# RZT2ME register map
Vendor: Renesas Electronics Corporation; Series: RZT; File version: 1.00.00
CPU: other r0p0, little endian, MPU, no FPU, VTOR, 4 interrupt priority bits, 624 interrupts
Registers are 32-bit, read-write, reset 0x0 unless marked. A register's access mark holds for its fields unless they carry their own. Offsets are from the block's base; [hi:lo] are bit positions; lines under a group give offsets from that group; {n}, {i} and the like mark numbered series.

## ETHSW (part 3 of 3) — Ethernet Switch
Base 0x80120000
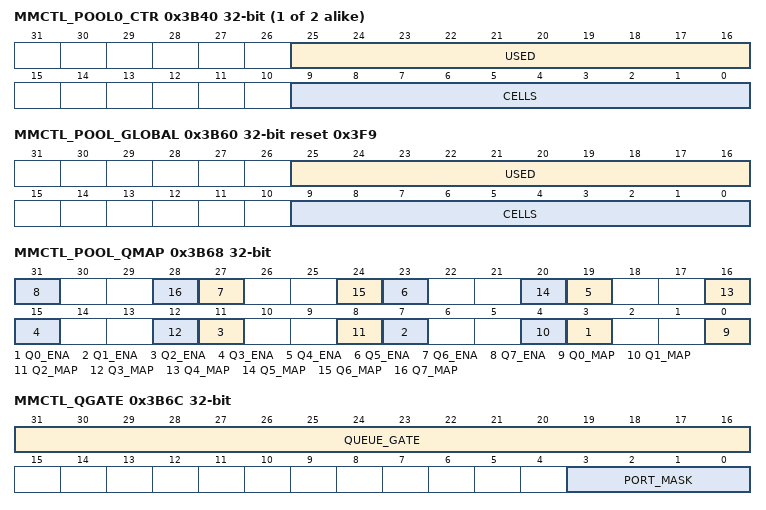
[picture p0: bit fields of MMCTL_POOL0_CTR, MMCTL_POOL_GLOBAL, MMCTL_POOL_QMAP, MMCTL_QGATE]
{0x3B40+4i} MMCTL_POOL{i}_CTR (i=0..1) — Memory Pool Counter (n = 0 to 1)
  [25:16] USED ro — Reports the current available number of used cells for this memory pool. The used number of free cells can be calculated as CELLS - USED.
  [9:0] CELLS — Memory pool configuration for pool n. Configures, in cells, the size of each memory pool.
0x3B60 MMCTL_POOL_GLOBAL reset 0x3F9 — Memory Pool Configuration Register
  [25:16] USED ro — Reports the current number of used cells for the global shared pool. The used number of free cells can be calculated as CELLS - USED.
  [9:0] CELLS — Memory pool configuration for the global pool. Configures, in cells, the size of the global shared pool.
0x3B64 MMCTL_POOL_STATUS ro — Memory Pool Status Register
  [7:0] QUEUE_FULL — Per-queue pool full indication. Indicates for each queue whether all the blocks in the corresponding pool and global pool are allocated.
0x3B68 MMCTL_POOL_QMAP — Queue MAP Register
  [4n+3] Q{n}_ENA (n=0..7) — Queue {n} Memory Pool Enabled
    0=The queue only uses cells from the global pool; 1=The queue uses the pool programmed in Q{n}_MAP
  [4n] Q{n}_MAP (n=0..7) — Queue {n} Memory Pool
0x3B6C MMCTL_QGATE wo — Queue Gate State Register
  [31:16] QUEUE_GATE — 2-bit per queue indicating the action to be performed on each queue of the ports indicated by PORT_MASK.
    0=Hold state, does not change the queue gate state; 1=Toggle state, toggles the gate state; 2=Gate queue, closes the queue; 3=Open queue, enables the queue
  [3:0] PORT_MASK — Per-port bit mask. When set to 1 for a port, the queue gate state is changed for that port as indicated by QUEUE_GATE.
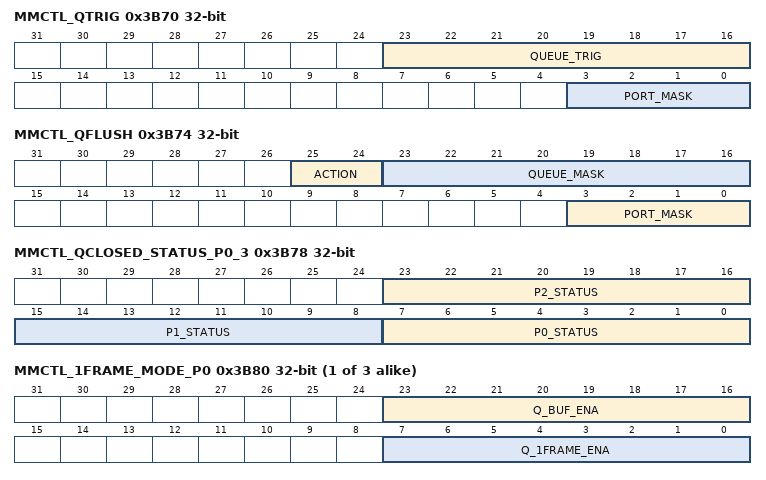
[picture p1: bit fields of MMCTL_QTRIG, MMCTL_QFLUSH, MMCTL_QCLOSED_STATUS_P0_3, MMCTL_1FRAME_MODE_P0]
0x3B70 MMCTL_QTRIG wo — Queue Trigger Register
  [23:16] QUEUE_TRIG — 1-bit per queue indicating from which queues a frame is to be transmitted from the ports indicated by PORT_MASK. When set to 1, a single frame is transmitted per indicated port in PORT_MASK among the queues indicated by QUEUE_TRIG.
  [3:0] PORT_MASK — Per-port bit mask. When set to 1 for a port, a frame is triggered from the closed queues indicated by QUEUE_TRIG.
0x3B74 MMCTL_QFLUSH wo — Flush Event Select Register
  [25:24] ACTION — Selects the flush state for the queues indicated by QUEUE_MASK in the ports indicated by PORT_MASK. Possible actions are:
    0=Disable flush; 1=Flush when queue is closed, discarding any new frames; 2=Flush on queue close until empty, then stops flushing; 3=TRIGGER flush until empty, then return to current flush mode
  [23:16] QUEUE_MASK — 1 bit per queue indicating for which queues of the ports indicated by PORT_MASK the flush state is changed as indicated in ACTION.
  [3:0] PORT_MASK — Per-port bit mask. When set to 1 for a port, the queue flush status is changed for that port for the queues indicated in QUEUE_MASK.
0x3B78 MMCTL_QCLOSED_STATUS_P0_3 ro — Queue Closed Status Register
  [23:16] P2_STATUS — Per-queue closed status of Port 2 (1-bit per queue). A 0 indicates that the queue is open (enabled), and a 1 indicates that the queue is closed (disabled).
  [15:8] P1_STATUS — Per-queue closed status of Port 1 (1-bit per queue). A 0 indicates that the queue is open (enabled), and a 1 indicates that the queue is closed (disabled).
  [7:0] P0_STATUS — Per-queue closed status of Port 0 (1-bit per queue). A 0 indicates that the queue is open (enabled), and a 1 indicates that the queue is closed (disabled).
{0x3B80+4i} MMCTL_1FRAME_MODE_P{i} (i=0..2) — Port {i} 1-Frame Mode Configuration Register
  [23:16] Q_BUF_ENA — 1 bit per queue. Setting a bit to 1 enables the buffer mode behavior for that queue for port n. This mode requires also that Q_1FRAME_ENA is set to 1.
  [7:0] Q_1FRAME_ENA — 1 bit per queue. Setting a bit to 1 enables the 1-frame mode for that queue for port n. In this mode, only one frame is allowed in the queue. If a new frame is received, the old frame is discarded.
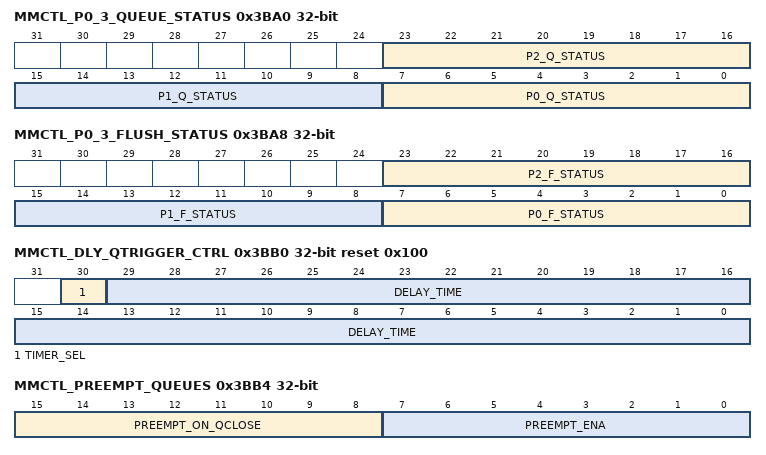
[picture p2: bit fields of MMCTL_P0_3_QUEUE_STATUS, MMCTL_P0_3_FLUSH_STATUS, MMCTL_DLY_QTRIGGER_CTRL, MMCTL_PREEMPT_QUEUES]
0x3BA0 MMCTL_P0_3_QUEUE_STATUS ro — Queue Status Indicator
  [all] fields
    0=Queue is empty; 1=Queued frames
  [23:16] P2_Q_STATUS — Port 2 Per-Queue Bit Indication
  [15:8] P1_Q_STATUS — Port 1 Per-Queue Bit Indication
  [7:0] P0_Q_STATUS — Port 0 Per-Queue Bit Indication
0x3BA8 MMCTL_P0_3_FLUSH_STATUS ro — Queue Flush Status Indicator
  [23:16] P2_F_STATUS — Port 2 per-Queue Bit Indication on whether the queue is flushing frames (read 1) or not (read 0).
  [15:8] P1_F_STATUS — Port 1 per-Queue Bit Indication on whether the queue is flushing frames (read 1) or not (read 0).
  [7:0] P0_F_STATUS — Port 0 per-Queue Bit Indication on whether the queue is flushing frames (read 1) or not (read 0).
0x3BB0 MMCTL_DLY_QTRIGGER_CTRL reset 0x100 — Delayed Queue Trigger Control Register
  [30] TIMER_SEL — Select the source timer to use for calculating the time.
    0=Timer 0; 1=Timer 1
  [29:0] DELAY_TIME — 30-bit time in nanoseconds indicates the time after the trigger request from the pattern matchers to generate the event.
0x3BB4 MMCTL_PREEMPT_QUEUES — Preemptable Queues Configures Register
  [15:8] PREEMPT_ON_QCLOSE — Per-queue configuration bit to enable preempting a frame when the queue goes from OPEN to CLOSED. When the corresponding bit is set to 1 and the queue is configured as preemptable in PREEMPT_ENA, a queue close event causes the current frame to be preempted, if preemption is operational.
  [7:0] PREEMPT_ENA — Per-queue enable bit to configure which queues are used for preemptable traffic. Set to 1 the corresponding bit to configure a queue to be preemptable.
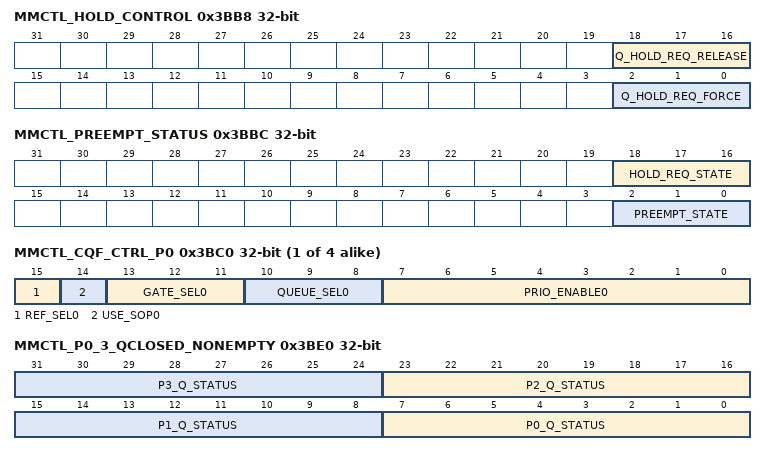
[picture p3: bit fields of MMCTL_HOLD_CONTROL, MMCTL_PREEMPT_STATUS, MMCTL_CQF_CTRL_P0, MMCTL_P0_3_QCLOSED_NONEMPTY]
0x3BB8 MMCTL_HOLD_CONTROL — Request Preemption Register
  [18:16] Q_HOLD_REQ_RELEASE — A per-port bit that forces a release of preemption request using MM_CTL.request (hold_req). When this bit is set to 1, it overrides other sources of hold request, including the TDMA controller and Q_HOLD_REQ_FORCE[2:0].
  [2:0] Q_HOLD_REQ_FORCE — A per-port bit that forces a preempt request using MM_CTL.request (hold_req). When this bit is set to 1, it overrides other sources of hold request, including the TDMA controller.
0x3BBC MMCTL_PREEMPT_STATUS ro — Preemption State Register
  [18:16] HOLD_REQ_STATE — A per-port bit that indicates if a port is preempted using MM_CTL.request (hold_req). This is a real-time indication meant for debugging.
  [2:0] PREEMPT_STATE — A per-port bit that indicates if a port is in a preempted state. This is a real-time indication meant for debugging.
{0x3BC0+4i} MMCTL_CQF_CTRL_P{i} (i=0..3) — Port {i} Cyclic Queuing and Forwarding Control Register (n = 0 to 3)
  [15] REF_SEL0 — Select whether the gate control signal used for the CQF group is based on the egress port when set to 0, or the ingress port when set to 1.
  [14] USE_SOP0 — When set to 1, the CFQ queue is determined when the SOP is received at the frame writer in the memory controller. When set to 0, the queue is determined when the EOP is received at the frame writer.
  [13:11] GATE_SEL0 — Select which gate control signal is used for selecting the output queue (these signals are the same as the ETHSW_TDMAOUT pins).
  [10:8] QUEUE_SEL0 — Select which two physical queues are used for CQF. The queues used are QUEUE_SEL0 and QUEUE_SEL0 + 1. Frames are written into QUEUE_SEL0 when the gate control selected with GATE_SEL0 is 0, and into QUEUE_SEL0 + 1 when the gate control is 1.
  [7:0] PRIO_ENABLE0 — A per-queue enable to select which ingress priorities are queued in the two CQF queues.
0x3BE0 MMCTL_P0_3_QCLOSED_NONEMPTY ro — Port Queue Status Register
  [8n+7:8n] P{n}_Q_STATUS (n=0..3) — Port {n} per-queue bit indication on whether the queue transitioned from open to closed state while frames were still queued.
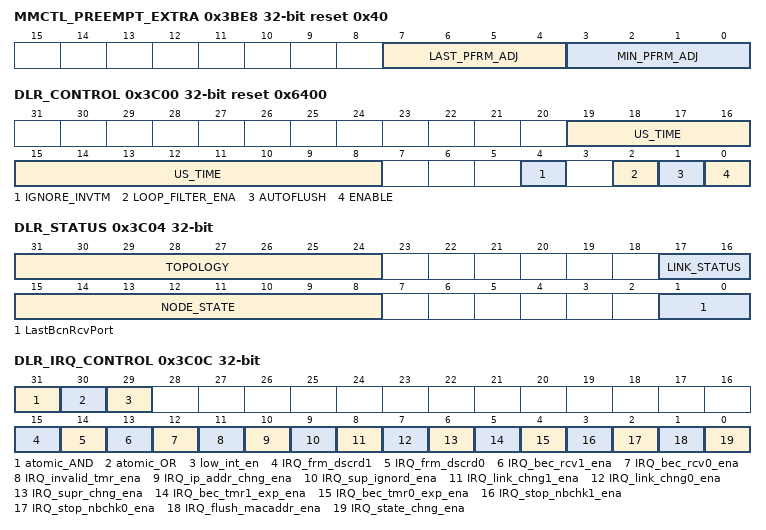
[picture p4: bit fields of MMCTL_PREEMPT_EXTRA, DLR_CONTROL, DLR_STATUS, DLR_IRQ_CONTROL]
0x3BE8 MMCTL_PREEMPT_EXTRA reset 0x40 — Frame Preemption Extra Configuration Register
  [7:4] LAST_PFRM_ADJ — Adjust the preemptable threshold when reaching the end of the frame, in increments of 4 bytes. Incrementing this value increments the length of the last mPacket.
  [3:0] MIN_PFRM_ADJ — Adjust the minimum mPacket length, in increments of 4 bytes.
0x3C00 DLR_CONTROL reset 0x6400
  [19:8] US_TIME — Number of clock cycles required for 1 microsecond for the switch operating clock. This LSI operates at 200 MHz, therefore this register must be set to 0xC8. The value after reset must be changed.
  [4] IGNORE_INVTM — Enable ignore beacon frames with invalid timeout timer. When enabled (set to 1) frames with timeout timer value not within a range of 200 microseconds to 500 milliseconds are ignored and parameters are not locally stored or considered for state transitions. The invalid timeout timer value is always stored within the DLR_INV_TMOUT register irrespective of the value of this bit. Ignored frames are forwarded normally.
  [2] LOOP_FILTER_ENA — Enable the loop filter function. When set to 1, the ingress loop filter is enabled. This can be enabled regardless of the DLR ENABLE state, allowing the loop filter function to operate when DLR is not used.
  [1] AUTOFLUSH — Enable automatic flushing of unicast entries in address table if ring reconfiguration occurs (see also DLR interrupt IRQ_flush_macaddr_ena in DLR_IRQ_CONTROL).
  [0] ENABLE — Enable DLR extension module. When set, the DLR module becomes active. When DLR is enabled, the LOOP_FILTER_ENA must also be enabled for proper DLR operation.
0x3C04 DLR_STATUS ro
  [31:24] TOPOLOGY — Current Network Topology
    0=Linear topology when local node is in IDLE state; 1=Ring topology when local node is not in IDLE state; other=Others (Reserved)
  [17:16] LINK_STATUS
  [15:8] NODE_STATE — Local Node Current State
    0=IDLE_STATE; 1=NORMAL_STATE; 2=FAULT_STATE; other=Others (Reserved)
  [1:0] LastBcnRcvPort — Last Beacon Receive Port
0x3C08 DLR_ETH_TYP reset 0x80E1 — DLR Ethernet Type Register
  [15:0] DLR_ETH_TYP — Ethernet type to compare for DLR frame detection (initial value is 0x80E1)
0x3C0C DLR_IRQ_CONTROL — DLR Interrupt Control Register
  [31] atomic_AND wo — When set during a register-write, the enable bits are ANDed with the current setting of the register. By writing this bit at the same time, only the target bit can be set to 0.
  [30] atomic_OR wo — When set during a register-write, the enable bits are ORed into the current setting of the register. By writing this bit at the same time, only the target bit can be set to 1.
  [29] low_int_en — Enable active-low interrupt. Asserted to use active-low interrupt signal instead of active-high interrupt signal.
  [15] IRQ_frm_dscrd1 — Enable Interrupt on Frame discard due to source address match with the local address on port 1.
  [14] IRQ_frm_dscrd0 — Enable interrupt on frame discard due to source address match with the local address on port 0.
  [13] IRQ_bec_rcv1_ena — Enable interrupt on beacon frame detection on port 1.
  [12] IRQ_bec_rcv0_ena — Enable interrupt on beacon frame detection on port 0.
  [11] IRQ_invalid_tmr_ena — Enable interrupt on invalid range for beacon timeout timer value detection.
  [10] IRQ_ip_addr_chng_ena — Enable interrupt on IP address change detection within beacon frame from ring supervisor.
  [9] IRQ_sup_ignord_ena — Enable interrupt on beacon frame detection from a supervisor with lower precedence than the current ring supervisor or lower numeric value for MAC address when precedence is same.
  [8] IRQ_link_chng1_ena — Enable Link Status Change Interrupt Event for Port 1.
  [7] IRQ_link_chng0_ena — Enable Link Status Change Interrupt Event for Port 0.
  [6] IRQ_supr_chng_ena — Enable Interrupt on Ring Supervisor Change.
  [5] IRQ_bec_tmr1_exp_ena — Enable Interrupt on Beacon Timeout Timer Expire for Port 1.
  [4] IRQ_bec_tmr0_exp_ena
  [3] IRQ_stop_nbchk1_ena — Enable Stop Request Neighbor Check Timeout Timer Interrupt for Port 1.
  [2] IRQ_stop_nbchk0_ena — Enable Stop Request Neighbor Check Timeout Timer Interrupt for Port 0.
  [1] IRQ_flush_macaddr_ena — Enable Flush Local MAC Address Table Interrupt.
  [0] IRQ_state_chng_ena — Enable Interrupt for State Change
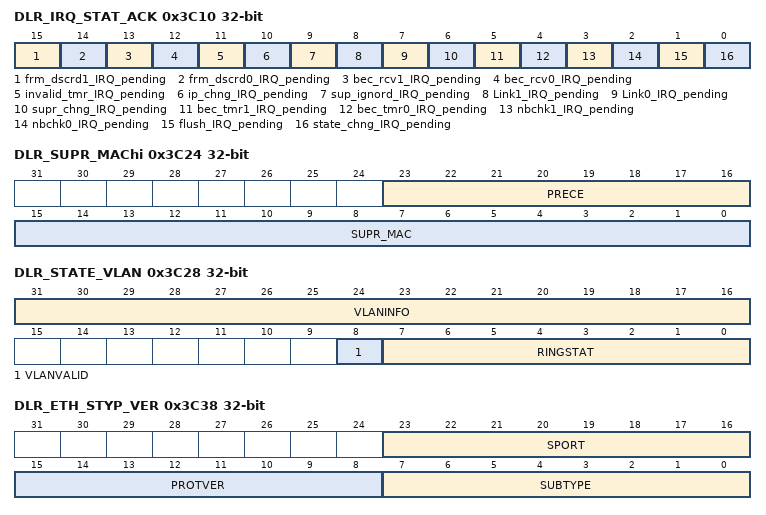
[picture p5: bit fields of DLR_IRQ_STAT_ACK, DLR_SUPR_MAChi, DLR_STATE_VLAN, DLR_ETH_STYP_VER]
0x3C10 DLR_IRQ_STAT_ACK — DLR Interrupt Status/ACK Register
  [15] frm_dscrd1_IRQ_pending — Latched Event on Frame Discard Due to Source Address Match with the Local Address on Port 1 (Loop Filter)
  [14] frm_dscrd0_IRQ_pending — Latched Event on Frame Discard Due to Source Address Match with the Local Address on Port 0 (Loop Filter)
  [13] bec_rcv1_IRQ_pending — Latched Event on Beacon Frame Detection on Port 1
  [12] bec_rcv0_IRQ_pending — Latched Event on Beacon Frame Detection on Port 0
  [11] invalid_tmr_IRQ_pending — Latched Event on Invalid Beacon Timeout Timer Value Detection Within Beacon Frame on Port 0 or Port 1
  [10] ip_chng_IRQ_pending — Latched IP Address Change Event
  [9] sup_ignord_IRQ_pending — Latched Event for Beacon Frame Detection from Ignored Supervisor
  [8] Link1_IRQ_pending — Latched Link Status Change Event for Port 1
  [7] Link0_IRQ_pending — Latched Link Status Change Event for Port 0
  [6] supr_chng_IRQ_pending — Latched Supervisor Change Event
  [5] bec_tmr1_IRQ_pending — Beacon Timeout Timer Expire Event for Port 1
  [4] bec_tmr0_IRQ_pending — Beacon Timeout Timer Expire Event for Port 0
  [3] nbchk1_IRQ_pending — Stop Request Event for Neighbor Check Timeout Timer for Port 1
  [2] nbchk0_IRQ_pending — Stop Request Event for Neighbor Check Timeout Timer for Port 0
  [1] flush_IRQ_pending — Latched Flush Event for MAC Address Learning Table
  [0] state_chng_IRQ_pending — Latched State Change Event
0x3C14 DLR_LOC_MAClo — DLR Local MAC Address Low Register
  [31:0] LOC_MAC — First 4 octets of the Local MAC address for loop filter
0x3C18 DLR_LOC_MAChi — DLR Local MAC Address High Register
  [15:0] LOC_MAC — Last 2 octets of local MAC address for loop filter
0x3C20 DLR_SUPR_MAClo ro — DLR Supervisor MAC Address Low Register
  [31:0] SUPR_MAC — First 4 octets of the active ring supervisor of the MAC address extracted from the Source Address field of the beacon frame.
0x3C24 DLR_SUPR_MAChi ro — DLR Supervisor MAC Address High Register
  [23:16] PRECE — Precedence value of the ring supervisor extracted from the Supervisor precedence field of the beacon frame.
  [15:0] SUPR_MAC — Last 2 octets of the active ring supervisor of the MAC address extracted from the Source Address field of the beacon frame.
0x3C28 DLR_STATE_VLAN ro — DLR Ring Status/VLAN Register
  [31:16] VLANINFO — IEEE 802.1Q VLAN Tag control field extracted from the VLAN info field of the beacon frame.
  [8] VLANVALID
  [7:0] RINGSTAT — DLR ring state extracted from the Ring State field of the beacon frame.
    1=RING_NORMAL_STATE; 2=RING_FAULT_STATE; other=Others (Unused)
0x3C2C DLR_BEC_TMOUT ro — DLR Beacon Timeout Register
  [31:0] BEC_TMOUT — Beacon timeout timer value extracted from the Beacon Timeout in microseconds field of the beacon frame.
0x3C30 DLR_BEC_INTRVL ro — DLR Beacon Interval Register
  [31:0] BEC_INTRVL — Beacon interval extracted from the Beacon Interval field of the beacon frame
0x3C34 DLR_SUPR_IPADR ro — DLR Supervisor IP Address Register
  [31:0] SUPR_IPADR — IP address of the ring supervisor extracted from the Source IP address field of the beacon frame. A value of 0x0 can be received when supervisor has no IP address.
0x3C38 DLR_ETH_STYP_VER ro — DLR Sub Type/Protocol Version Register
  [23:16] SPORT — Source port extracted from the Source Port field of the beacon frame.
  [15:8] PROTVER — DLR Ring Protocol Version extracted from the Ring Protocol Version field of the beacon frame.
  [7:0] SUBTYPE — DLR Ring Ether Sub Type extracted from the Ring Sub Type field of the beacon frame.
0x3C3C DLR_INV_TMOUT ro — DLR Beacon Timeout Timer Register
  [31:0] INV_TMOUT — Last out of range Beacon timeout timer value extracted from beacon frame on any of the port.
0x3C40 DLR_SEQ_ID ro — DLR Sequence ID Register
  [31:0] SEQ_ID — Sequence ID of the last beacon frame extracted from the Sequence ID field of the beacon frame on port 0 or port 1. Sequence ID of the ignored frames is not stored.
0x3C58 DLR_DSTlo reset 0x6C2101 — DLR Beacon Destination Address Low Register
  [31:0] DLR_DST — First 4 octets of the beacon frame destination multicast address (01-21-6C-00-00-01).
0x3C5C DLR_DSThi reset 0x100 — DLR Beacon Destination Address High Register
  [15:0] DLR_DST — Last 2 octets of the beacon frame destination multicast address (01-21-6C-00-00-01).
0x3C60 DLR_RX_STAT0 ro — DLR Received Frame Statistic Register 0
  [31:0] RX_STAT0 — Number of Beacon Frames Received on Port 0
0x3C64 DLR_RX_ERR_STAT0 ro — DLR Received Frame Error Statistic Register 0
  [31:0] RX_ERR_STAT0 — Number of Beacon Frames Received with CRC Error on Port 0
0x3C6C DLR_RX_LF_STAT0 — DLR Received Frame Loop Filter Statistic Register 0
  [7:0] RX_LF_STAT0 — Number of discarded frames in port 0 due to loop filtering when LOOP_FILTER_ENA is set to 1. Saturates at 255.
0x3C70 DLR_RX_STAT1 ro — DLR Received Frame Statistic Register 1
  [31:0] RX_STAT1 — Number of Beacon Frames Received on Port 1
0x3C74 DLR_RX_ERR_STAT1 ro — DLR Received Frame Error Statistic Register 1
  [31:0] RX_ERR_STAT1 — Number of Beacon Frames Received with CRC Error on Port 1
0x3C7C DLR_RX_LF_STAT1 — DLR Received Frame Loop Filter Statistic Register 1
  [7:0] RX_LF_STAT1 — Number of discarded frames in port 1 due to loop filtering when LOOP_FILTER_ENA is set to 1. Saturates at 255.
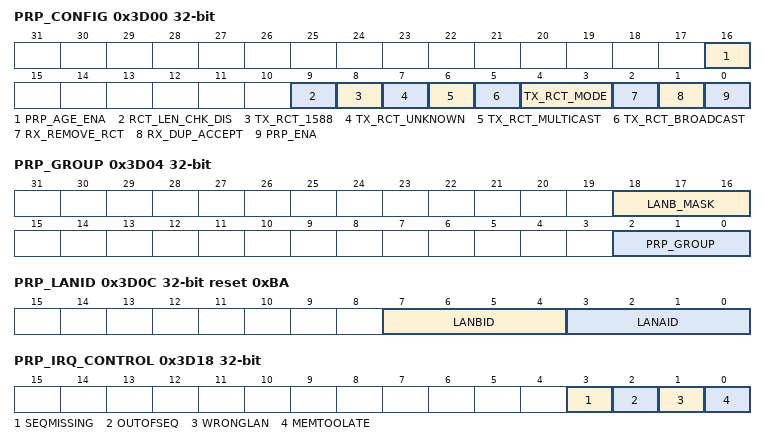
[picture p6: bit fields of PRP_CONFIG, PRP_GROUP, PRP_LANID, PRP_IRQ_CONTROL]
0x3D00 PRP_CONFIG — PRP Configuration Register
  [16] PRP_AGE_ENA — Enable History Memory Aging Timer
  [9] RCT_LEN_CHK_DIS — When set to 1, disables the RCT length field checking against the actual frame length.
  [8] TX_RCT_1588 — Setting this bit affects IEEE 1588 frames that are forwarded through the switch (for example, when used as RedBox) to both PRP_GROUP ports. Locally generated IEEE 1588 frames (peer-delay request/response) are not affected by this setting.
    0=Do not append RCT to IEEE 1588 frames (frame type 0x88F7) frames even if they are duplicated; 1=Allow appending RCT to IEEE 1588 frames. Defines to treat those frames as any other frame according to the configured TX_RCT_xxx settings above.
  [7] TX_RCT_UNKNOWN — Should be 1 normally.
    0=Do not append RCT to frames flooded because the destination is unknown. This further restricts modes 00b, 01b, 11b.; 1=Allow appending RCT to frames that have unknown destination and are hence flooded
  [6] TX_RCT_MULTICAST — Should be 1 normally.
    0=Do not append RCT to multicast frames. This further restricts modes 00b, 01b, 11b.; 1=Allow appending RCT to multicast frames
  [5] TX_RCT_BROADCAST — Should be 1 normally.
    0=Do not append RCT to broadcast frames. This further restricts modes 00b, 01b, 11b.; 1=Allow appending RCT to broadcast frames
  [4:3] TX_RCT_MODE — Control Appending the RCT to Transmitted Frames on the Redundant Ports
    0=Append RCT if group only: Append RCT, if frame is duplicated to exactly the ports listed in the PRP_GROUP register. If the frame is sent to only one of the ports or is for example, flooded also to other ports, no RCT is appended.; 1=Append RCT to group always: Append the RCT always if the frame is duplicated to at least the two ports listed in the PRP_GROUP. This includes flooded frames even if they are additionally sent on other ports outside the PRP_GROUP. If the frame is sent to only one of the PRP_GROUP ports, no RCT is appended.; 2=Disable RCT append: The transmitters do not append the RCT even if frames are duplicated to the PRP_GROUP ports. This represents the IEC: 4.2.6 duplicate accept mode of operation.; 3=Append RCT always forced: The transmitters append the RCT to all frames transmitted on any of the PRP_GROUP ports, no matter if they are duplicated or not or if they are flooded
  [2] RX_REMOVE_RCT — Allow PRP Port RX to Remove the RCT
  [1] RX_DUP_ACCEPT — Enable Duplicate Accept Mode of Operation at Receive
  [0] PRP_ENA — Enable PRP Operation
0x3D04 PRP_GROUP — PRP Port Group Register
  [18:16] LANB_MASK — Defines which of the ports is considered the LAN B port.
  [2:0] PRP_GROUP — Defines which two ports should be treated as redundant ports for PRP.
0x3D08 PRP_SUFFIX reset 0x88FB — PRP RCT Suffix
  [15:0] PRP_SUFFIX — The Redundancy Control Trailer (RCT) suffix (initial value is 0x88FB)
0x3D0C PRP_LANID reset 0xBA — PRP LAN Identifier
  [7:4] LANBID — LAN B Identifier
  [3:0] LANAID — LAN A Identifier
0x3D10 DUP_W — PRP Max Duplicate Detection Window Size
  [7:0] DUP_W — Maximum Duplicate Detect Window Size
0x3D14 PRP_AGETIME — PRP Aging Time Define Register
  [23:0] PRP_AGETIME — Timeout in steps of 32 switch operating clock cycles to control aging of duplicate history data.
0x3D18 PRP_IRQ_CONTROL — PRP Interrupt Control Register
  [3] SEQMISSING — Enable interrupt for frames received and accepted that caused the history to skip a sequence number that was never received (for example, a missing sequence number is being ignored and is now treated as a candidate for dropping).
  [2] OUTOFSEQ — Enable interrupt for frames received and accepted but have an unexpected sequence number.
  [1] WRONGLAN — Enable interrupt for frames received at a redundant port with an invalid LAN identifier in its redundancy trailer.
  [0] MEMTOOLATE — Enable Interrupt for Memory Error Indications.
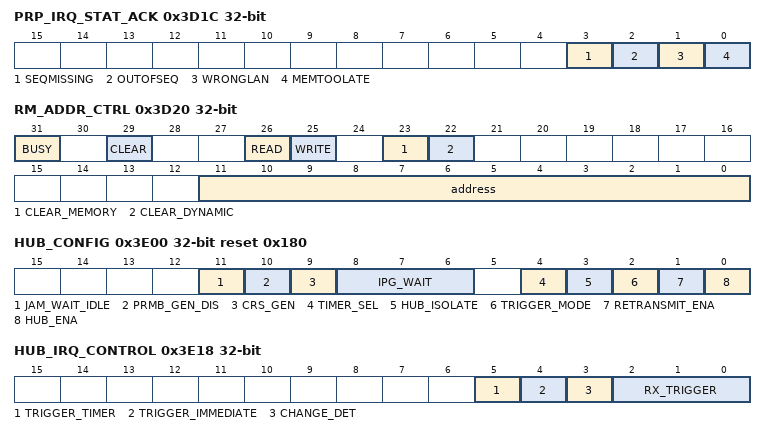
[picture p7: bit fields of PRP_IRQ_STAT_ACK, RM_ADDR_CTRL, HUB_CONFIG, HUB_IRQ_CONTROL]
0x3D1C PRP_IRQ_STAT_ACK — PRP Interrupt Status/ACK Register
  [3] SEQMISSING — This bit functions the same as MEMTOOLATE bit.
  [2] OUTOFSEQ — This bit functions the same as MEMTOOLATE bit.
  [1] WRONGLAN — This bit functions the same as MEMTOOLATE bit.
  [0] MEMTOOLATE — Interrupt Pending Indication
0x3D20 RM_ADDR_CTRL — PRP History Memory Transactions Control Register
  [31] BUSY ro — Transaction Busy Indication
  [29] CLEAR — When set to 1, write all 0s to the entry selected by the given address.
  [26] READ — When set to 1, perform Single Read Transaction.
  [25] WRITE — When set to 1, perform a Single Write Transaction.
  [23] CLEAR_MEMORY — When set to 1, write all memory locations with 0.
  [22] CLEAR_DYNAMIC — When set to 1, scan the complete table for valid dynamic history entries and deletes them (writes entry with all 0s).
  [11:0] address — Memory Address for Read and Write Transactions
0x3D24 RM_DATA — PRP Memory Data Register
  [31:0] RM_DATA — Memory data register for read/write transactions controlled by RM_ADDR_CTRL.
0x3D28 RM_DATA_HI — PRP Memory Data Higher Register
  [31:0] RM_DATA_HI — A Second Data Register
0x3D2C RM_STATUS ro — PRP Memory Controller Status Indication
  [11:0] ageaddress — Address of an entry which the aging process inspects when the aging timer expires next time.
0x3D30 TxSeqTooLate — PRP Frame Transmission Retrieval of Failed Sequence
  [3:0] TxSeqTooLate — Retrieval of a Sequence Number Failed
0x3D34 CntErrWrongLanA ro — PRP Wrong ID LAN-A Count Register
  [31:0] CntErrWrongLanA — Valid frames received on LAN A which have an RCT (valid length + suffix) but LAN ID is not matching LAN A.
0x3D38 CntErrWrongLanB ro — PRP Wrong ID LAN-B Count Register
  [31:0] CntErrWrongLanB — Valid frames received on LAN B which have an RCT (valid length + suffix) but LAN ID is not matching LAN B.
0x3D3C CntDupLanA ro — PRP Duplicate LAN-A Count Register
  [31:0] CntDupLanA — Valid frames received on LAN A that were dropped by duplicate detection.
0x3D40 CntDupLanB ro — PRP Duplicate LAN-B Count Register
  [31:0] CntDupLanB — Valid frames received on LAN B that were dropped by duplicate detection.
0x3D44 CntOutOfSeqLowA ro — PRP Sequence Error Low LAN-A Count Register
  [31:0] CntOutOfSeqLowA — Valid and accepted frames received on LAN A with a sequence number less than last window (DUP_W).
0x3D48 CntOutOfSeqLowB ro — PRP Sequence Error Low LAN-B Count Register
  [31:0] CntOutOfSeqLowB — Valid and accepted frames received on LAN B with a sequence number less than last window (DUP_W).
0x3D4C CntOutOfSeqA ro — PRP Sequence Error LAN-A Count Register
  [31:0] CntOutOfSeqA — Valid and accepted frames received on LAN A with an unexpected sequence number.
0x3D50 CntOutOfSeqB ro — PRP Sequence Error LAN-B Count Register
  [31:0] CntOutOfSeqB — Valid and accepted frames received on LAN B with an unexpected sequence number.
0x3D54 CntAcceptA ro — PRP Valid Frame LAN-A Count Register
  [31:0] CntAcceptA — Valid frames received on LAN A which had a valid sequence number in the expected range.
0x3D58 CntAcceptB ro — PRP Valid Frame LAN-B Count Register
  [31:0] CntAcceptB — Valid frames received on LAN B which had a valid sequence number in the expected range.
0x3D5C CntMissing ro — PRP Drop History Adjustment Count
  [31:0] CntMissing — Indicates adjustment of the drop history as a frame was received with a sequence number of expected + history + 1. This occurs if the same frame was dropped in both LAN segments (one sequence number is missing) and the history is now extended beyond that sequence number (causing it to be treated as drop allowed).
0x3E00 HUB_CONFIG reset 0x180 — HUB Configuration Register
  [11] JAM_WAIT_IDLE
  [10] PRMB_GEN_DIS
  [9] CRS_GEN
  [8:6] IPG_WAIT
  [4] TIMER_SEL — Select the timer to use for timed triggers
    0=Timer 0; 1=Timer 1
  [3] HUB_ISOLATE — Isolate all hub ports from the other ports of the switch and allow communication with management port only. It is then up to the application of the management port to implement some bridging functionality to other ports as required.
  [2] TRIGGER_MODE — Enable Single Frame Trigger Mode
  [1] RETRANSMIT_ENA — Enable Hub Retransmit Capability
  [0] HUB_ENA — Enable Integrated HUB Operation
0x3E04 HUB_GROUP — HUB Port Group Register
  [2:0] HUB_GROUP — Define all ports that should be combined to a Hub Group.
0x3E08 HUB_DEFPORT — HUB Default Port Selection Register
  [2:0] HUB_DEFPORT — The default port within the Hub Group where all traffic from a port outside the group is forwarded to port (bit 0 = port 0, bit 1 = port 1, and bit 2 = port 2). If a frame should be forwarded to any of the hub ports, the frame is sent to this port only. The copy function of the hub copies it to all PHY interfaces of the group eventually.
0x3E0C HUB_TRIGGER_IMMEDIATE — HUB Transmission Trigger Immediate Register
  [2:0] HUB_TRIGGER_IMMEDIATE — Trigger immediate transmission of a single frame from given port within the hub group (bit 0 = port 0, bit 1 = port 1, and bit 2 = port 2).
0x3E10 HUB_TRIGGER_AT — HUB Transmission Trigger At Register
  [2:0] HUB_TRIGGER_AT — Trigger Transmission of a Single Frame at a Specific Time (bit 0 = port 0, bit 1 = port 1, and bit 2 = port 2).
0x3E14 HUB_TTIME — HUB Transmission Time Define Register
  [31:0] HUB_TTIME — Define the Time Value when a Trigger Should Occur
0x3E18 HUB_IRQ_CONTROL — HUB Interrupt Control Register
  [5] TRIGGER_TIMER — Enable interrupt when hub transmit started after writing the HUB_TRIGGER_TIME register and the timeout value is reached (register HUB_TTIME).
  [4] TRIGGER_IMMEDIATE — Enable interrupt when hub transmit started after writing the HUB_TRIGGER_IMMEDIATE register
  [3] CHANGE_DET — Enable interrupt for hub TX state machine port state change request detection
  [2:0] RX_TRIGGER — Enable Interrupt on Receive Pattern Match Trigger Function
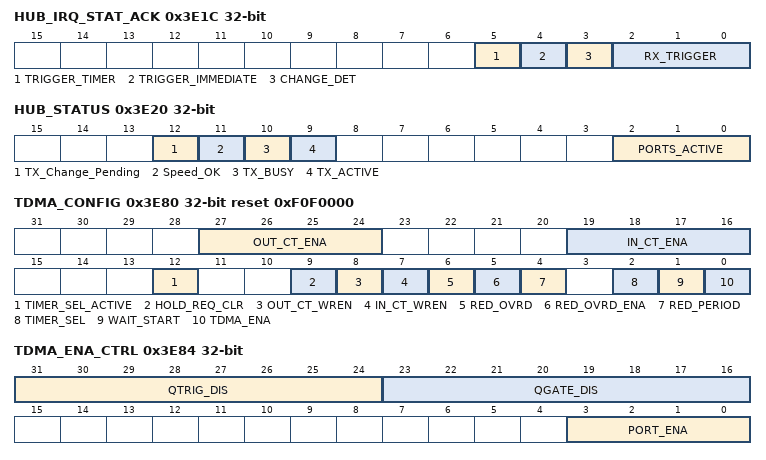
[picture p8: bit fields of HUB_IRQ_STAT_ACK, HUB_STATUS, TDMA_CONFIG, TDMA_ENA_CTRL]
0x3E1C HUB_IRQ_STAT_ACK — HUB Interrupt Status/ACK Register
  [5] TRIGGER_TIMER — This bit functions the same as RX_TRIGGER bit.
  [4] TRIGGER_IMMEDIATE — This bit functions the same as RX_TRIGGER bit.
  [3] CHANGE_DET — This bit functions the same as RX_TRIGGER bit.
  [2:0] RX_TRIGGER — Interrupt Pending Indication
0x3E20 HUB_STATUS ro
  [12] TX_Change_Pending — Indicate a pending change request in the hub transmitter that is unsolved and cause the hub to stop operation (no longer performing any transmissions).
  [11] Speed_OK — When this bit is 1, it indicates that the port speed of all group ports match.
  [10] TX_BUSY — When this bit is 1, the local device currently transmits data to all ports within the hub group.
  [9] TX_ACTIVE — When this bit is 1, the hub global transmit state machine has successfully entered Hub mode and is now controlling the hub group.
  [2:0] PORTS_ACTIVE — When this bit is 1, it shows the currently active ports of the Hub group which are allowed for transmit.
0x3E24 HUB_OPORT_STATUS ro — HUB Output Port Status Register
  [2:0] HUB_OPORT_STATUS — Per Output Port Data Available Status
0x3E80 TDMA_CONFIG reset 0xF0F0000 — TDMA Configuration Register
  [27:24] OUT_CT_ENA — On read, return the current status of the egress Cut-Through enable indicated by the TDMA scheduler. On write, override the egress Cut-Through enable if OUT_CT_WREN is also 1.
  [19:16] IN_CT_ENA — On read, return the current status of the ingress Cut-Through enable indicated by the TDMA scheduler. On write, override the ingress Cut-Through enable if IN_CT_WREN is also 1.
  [12] TIMER_SEL_ACTIVE ro — Return the current timer being used for the TDMA Scheduler
    0=Timer 0; 1=Timer 1
  [9] HOLD_REQ_CLR wo — Writing 1 to this register clears the state of TDMA hold request.
  [8] OUT_CT_WREN wo — Enable writing the OUT_CT_ENA control to the egress ports.
  [7] IN_CT_WREN wo
  [6] RED_OVRD — Override Value for the RED Period
  [5] RED_OVRD_ENA — Enables overriding the RED period status, regardless of the indication by the TCV.
  [4] RED_PERIOD ro — Read only bit indicating the current period for Profinet
  [2] TIMER_SEL — Select which timer to use as the time source for the scheduler
    0=Timer 0; 1=Timer 1
  [1] WAIT_START ro — Status bit which is set as long as the scheduler is enabled but has not yet reached the time given in register TDMA_START.
  [0] TDMA_ENA — Enable TDMA Scheduler
0x3E84 TDMA_ENA_CTRL — TDMA Scheduling Enable Control Register
  [31:24] QTRIG_DIS — One bit per output queue. When a bit is set to 1, the TDMA scheduler triggering commands do not affect the queue even if the queue mask in the TCV control data is set to 1.
  [23:16] QGATE_DIS — One bit per output queue. When a bit is set to 1, the TDMA scheduler gating commands do not affect the queue even if the queue mask in the TCV control data is set to 1.
  [3:0] PORT_ENA — Set to 1 to indicate that a port is operating in TDMA mode. When set to 1 for a port, the port does not prefetch another frame until the current frame in progress is done and if TDMA_PREBUF_DIS in COMMAND_CONFIG is set to 1. This helps adding precision to the queue gating operations indicated by the TDMA at the expense of loss of line rate.
0x3E88 TDMA_START — TDMA Start Time Set Register
  [31:0] TDMA_START — Set the start time for the very first cycle after system initialization has completed. The value is compared with the system time (selected in TDMA_CONFIG.TIMER_SEL) and when it is reached (crossed), the scheduler begins with its first cycle. The 2nd cycle is then at TDMA_START + TDMA_CYCLE.
0x3E8C TDMA_MODULO — TDMA System Timer Modulo
  [31:0] TDMA_MODULO — The System Timer Modulo
0x3E90 TDMA_CYCLE — TDMA Periodic Cycle Set Register
  [31:0] TDMA_CYCLE — The periodic cycle time for the scheduler given in system timer time.
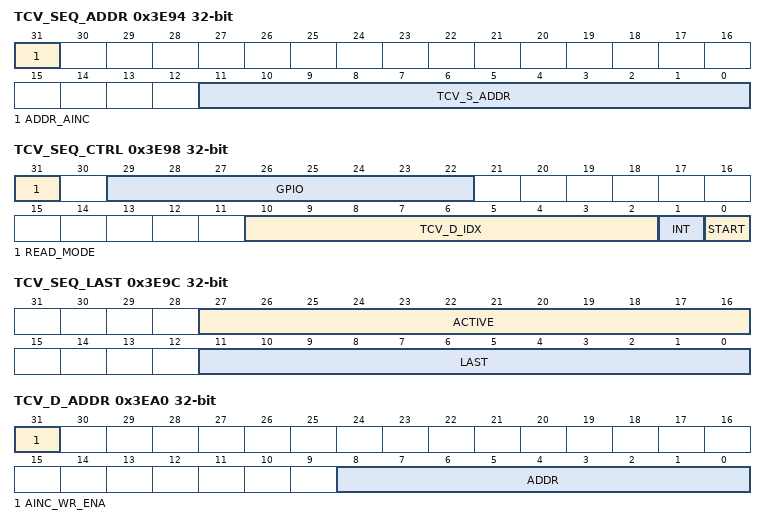
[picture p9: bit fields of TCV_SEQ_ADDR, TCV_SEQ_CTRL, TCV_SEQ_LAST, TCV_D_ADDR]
0x3E94 TCV_SEQ_ADDR — TCV Sequence Address Register
  [31] ADDR_AINC — When set to 1, read and write operations performed using TCV_SEQ_CTRL causes the address in TCV_S_ADDR to auto-increment after the operation.
  [11:0] TCV_S_ADDR — Address to write to or read from in the TCV sequence table.
0x3E98 TCV_SEQ_CTRL — TCV Sequence Table Control Register
  [31] READ_MODE — When set to 1, a read operation is performed instead of writing to the TCV sequence table. The read data (START, INT, TCV_D_IDX[8:0], and GPIO) can be obtained by reading this register afterwards. On read, this field always returns 0.
  [29:22] GPIO — Generic bits that control the output pins ETHSW_TDMAOUTn (n = 0 to 7)
  [10:2] TCV_D_IDX — Index to the TCV Data Entry
  [1] INT — Indicates this TCV generates an interrupt to the CPU when activated
  [0] START — Indicate this TCV must be executed after the next cycle start
0x3E9C TCV_SEQ_LAST — TCV Sequence Last Entry
  [27:16] ACTIVE ro — Return the active TCV sequence entry.
  [11:0] LAST — Defines the last entry to read from the TCV sequence table when the TDMA scheduler is operating.
0x3EA0 TCV_D_ADDR — TCV Data Address Register
  [31] AINC_WR_ENA — Auto-Increment Enable
  [8:0] ADDR — Address to read from/write to in the TCV data table
0x3EA4 TCV_D_OFFSET — TCV Data Offset Register
  [31:0] TCV_D_OFFSET — 32-bit time offset for the TCV data entry indicated by TCV_D_ADDR. When accessing the table, TCV_D_OFFSET must be read or written before TCV_D_CTRL.
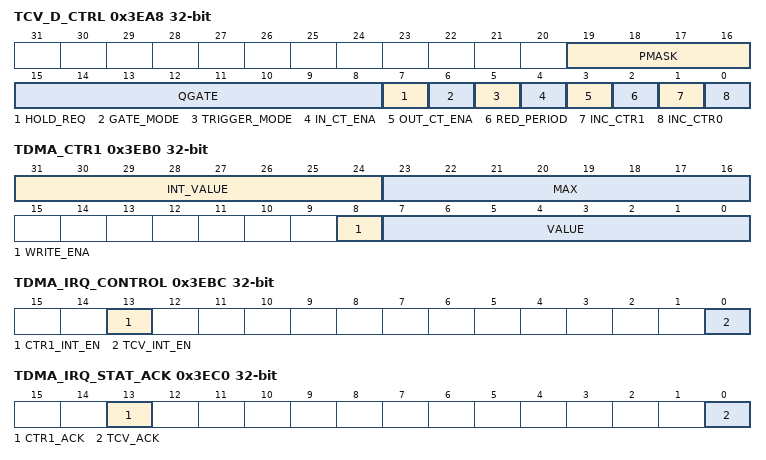
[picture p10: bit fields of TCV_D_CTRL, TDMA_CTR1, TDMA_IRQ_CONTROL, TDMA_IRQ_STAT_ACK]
0x3EA8 TCV_D_CTRL — TCV Data Control Register
  [19:16] PMASK — Bits mask, one per output port
  [15:8] QGATE — Bits mask, one per output queue
  [7] HOLD_REQ — Preemption hold request. Generates a hold request to ports enabled in PMASK.
  [6] GATE_MODE — Gate mode enable when set to 1.
  [5] TRIGGER_MODE — Trigger mode enable when set to 1. GATE_MODE must be 0, otherwise, GATE_MODE has precedence.
  [4] IN_CT_ENA — Input Cut-Through Enable
  [3] OUT_CT_ENA — Output Cut-Through Enable
  [2] RED_PERIOD — Period Color Control (for Profinet IRT)
  [1] INC_CTR1 — Increment Control for Counter 1
  [0] INC_CTR0 — Increment Control for Counter 0
0x3EAC TDMA_CTR0 — TDMA Counter 0
  [31:0] TDMA_CTR0 — 32-bit counter that is incremented when the TCV field INC_CTR0 is set to 1.
0x3EB0 TDMA_CTR1 — TDMA Counter 1
  [31:24] INT_VALUE — Interrupt Value
  [23:16] MAX — Counter Maximum Value
  [8] WRITE_ENA wo — Write Enable for VALUE
  [7:0] VALUE — Current Counter Value
0x3EB4 TDMA_TCV_START — TDMA TCV Sequence Entry Start
  [11:0] TDMA_TCV_START — Define the TCV_SEQ entry to start from.
0x3EB8 TIME_LOAD_NEXT ro — TDMA Calculated Next Loading Time
  [31:0] TIME_LOAD_NEXT — Status giving the calculated time the scheduler loads into its internal compare register after the current running slot end is reached (not the end of the current slot).
0x3EBC TDMA_IRQ_CONTROL
  [13] CTR1_INT_EN — Enable Interrupts Generated from Counter 1
  [0] TCV_INT_EN — Enable Interrupts Generated by the TCV
0x3EC0 TDMA_IRQ_STAT_ACK — TDMA IRQ Status/ACK Register
  [13] CTR1_ACK — Counter 1 Event
  [0] TCV_ACK — TCV Execution Event
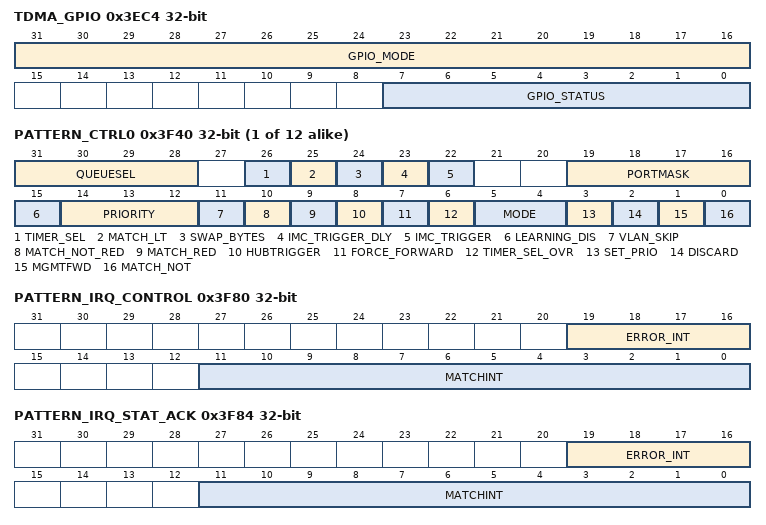
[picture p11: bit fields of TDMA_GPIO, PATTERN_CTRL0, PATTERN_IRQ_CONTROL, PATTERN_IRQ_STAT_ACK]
0x3EC4 TDMA_GPIO
  [31:16] GPIO_MODE — 2 bits per GPIO pin to configure its operating mode
  [7:0] GPIO_STATUS ro — Status of the GPIO Output Pins
{0x3F00+4i} RXMATCH_CONFIG{i} (i=0..3) — RX Pattern Matcher Configuration for Port {i}
  [11:0] PATTERN_EN — Enable Patterns on the Port (RX)
{0x3F40+4i} PATTERN_CTRL{i} (i=0..11) — RX Pattern Matcher Function Control for Pattern {i}
  [31:28] QUEUESEL — A queue selector for the HUBTRIGGER function. Selects the queue to trigger a frame, or sets from 0x8 to 0xF to select one among all queues.
  [26] TIMER_SEL — Override value to use when TIMER_SEL_OVR is set to 1 for selecting the timer for this frame.
    0=Timer 0; 1=Timer 1
  [25] MATCH_LT — For operating modes 1, 2, and 3. When set to 1, the Length/Type field in the frame after the MAC source address is compared against the value in length_type in the compare register. If VLAN_SKIP is set and the frame has a VLAN tag with Length/Type of 0x8100 then the comparison is performed in the Length/Type following the VLAN tag.
  [24] SWAP_BYTES — Applicable only for operating modes 1, 2, and 3. When set to 1, the byte order is swapped from the order received by the frame. When set to 0, the first byte received by the frame is set into position 0 for comparison. When set to 1, the first byte received is set into position 3 (for mode 1) or position 2 (for mode 2 and 3) for comparison.
  [23] IMC_TRIGGER_DLY — When set, the ports defined in the PORTMASK setting are allowed for transmitting one frame from the queues indicated by QUEUESEL. The trigger request is sent to the integrated memory controller and the event is delayed by the value programmed in MMCTL_DLY_QTRIGGER_CTRL.
  [22] IMC_TRIGGER — When set, the ports defined in the PORTMASK setting are allowed for transmitting one frame from the queues indicated by QUEUESEL. The trigger request is sent to the integrated memory controller.
  [19:16] PORTMASK — A port mask used depending on the control bits (for example, HUBTRIGGER).
  [15] LEARNING_DIS — When set to 1, the hardware learning function is not executed.
  [14:12] PRIORITY — Priority of the frame used when SET_PRIO is set. The priority is used to forward the frame into the corresponding output queue of a port.
  [11] VLAN_SKIP — When set to 1, for operating modes 1, 2, and 3. The first Length/Type after the MAC source address is compared against 0x8100. If it matches, a VLAN tag is assumed and 4 bytes are skipped.
  [10] MATCH_NOT_RED — Enable the pattern matcher only when the TDMA indicates that this is not the RED period.
  [9] MATCH_RED — Enable the pattern matcher only when the TDMA indicates that this is the RED period.
  [8] HUBTRIGGER — When set, the port defined in the PORTMASK setting is allowed for transmitting one frame.
  [7] FORCE_FORWARD — When set, the frame is forwarded to the ports indicated in PORTMASK, ignoring the result from L2 lookups.
  [6] TIMER_SEL_OVR — Overrides the default timer to use by timestamp operations when set to 1, using instead the value in TIMER_SEL.
  [5:4] MODE — Selects the operating mode
    0=Mode 1: Fixed 12-byte match; 1=Mode 2: 2-byte table lookup; 2=Mode 3: 2-byte range match at set offset; 3=Mode 4: 2-byte range not-match at set offset
  [3] SET_PRIO — Set frame priority, overriding normal classification.
  [2] DISCARD — When set, the frame is discarded.
  [1] MGMTFWD — When set, the frame is forwarded to the management port only (suppressing destination address lookup).
  [0] MATCH_NOT — When set, a match is reported and the functions of this control are executed if the pattern does not match.
0x3F80 PATTERN_IRQ_CONTROL — RX Pattern Matcher Interrupt Control Register
  [19:16] ERROR_INT — Enable Interrupt on Internal Pattern Matcher Error
  [11:0] MATCHINT — Enable Interrupt on Receive Pattern Match
0x3F84 PATTERN_IRQ_STAT_ACK — RX Pattern Matcher Interrupt Status/ACK Register
  [19:16] ERROR_INT — Interrupt pending indication for a pattern matcher error, per port.
  [11:0] MATCHINT — Interrupt pending indication for the corresponding pattern match events (see ).
0x3F88 PTRN_VLANID reset 0x8100 — Custom VLAN ID Register
  [15:0] PTRN_VLANID — Custom VLAN ID to use. The default VLAN ID 0x8100 is always considered by the hardware. This value can be changed to detect other VLANs like 0x8808.
0x3F8C PATTERN_SEL — RX Pattern Number Selection Register
  [3:0] PATTERN_SEL — Define the pattern number which is selected for read/write through the PTRN_CMP_* and PTRN_MSK_* registers.
0x3FC0 PTRN_CMP_30 — Pattern Compare Value Bytes 3 .. 0
0x3FC4 PTRN_CMP_74 — Pattern Compare Value Bytes 7 .. 4
0x3FC8 PTRN_CMP_118 — Pattern Compare Value Bytes 11 .. 8
0x3FD0 PTRN_MSK_30 — Pattern Mask for Bytes 3 .. 0
0x3FD4 PTRN_MSK_74 — Pattern Mask for Bytes 7 .. 4
0x3FD8 PTRN_MSK_118 — Pattern Mask for Bytes 11 .. 8
